VERSION ""

NS_ :

BS_:

BU_: PDU ELVIS ASSI ECU_LV Dashboard

BO_ 1285 ECU_error: 1 ECU_LV
 SG_ Error_code : 7|8@0+ (1,0) [0|255] "" Vector__XXX

BO_ 1 ECU_State: 1 ECU_LV
 SG_ Orion_state : 3|3@0+ (1,0) [0|7] "" Vector__XXX
 SG_ Heartbeat : 0|1@0+ (1,0) [0|1] "" Vector__XXX

BO_ 277 Brake_pressures: 4 ECU_LV
 SG_ Brake_rear : 23|16@0+ (0.004,0) [0|262.14] "" Vector__XXX
 SG_ Brake_front : 7|16@0+ (0.004,0) [0|262.14] "" Vector__XXX

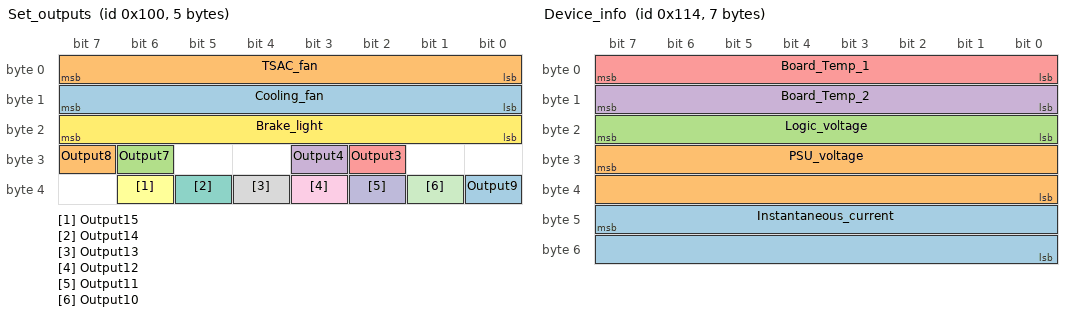
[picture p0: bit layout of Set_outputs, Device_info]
BO_ 256 Set_outputs: 5 PDU
 SG_ Output9 : 32|1@0+ (1,0) [0|1] "" Vector__XXX
 SG_ Output8 : 31|1@0+ (1,0) [0|1] "" Vector__XXX
 SG_ Output7 : 30|1@0+ (1,0) [0|1] "" Vector__XXX
 SG_ Output4 : 27|1@0+ (1,0) [0|1] "" Vector__XXX
 SG_ Output3 : 26|1@0+ (1,0) [0|1] "" Vector__XXX
 SG_ Output15 : 38|1@0+ (1,0) [0|1] "" Vector__XXX
 SG_ Output14 : 37|1@0+ (1,0) [0|1] "" Vector__XXX
 SG_ Output13 : 36|1@0+ (1,0) [0|1] "" Vector__XXX
 SG_ Output12 : 35|1@0+ (1,0) [0|1] "" Vector__XXX
 SG_ Output11 : 34|1@0+ (1,0) [0|1] "" Vector__XXX
 SG_ Output10 : 33|1@0+ (1,0) [0|1] "" Vector__XXX
 SG_ Brake_light : 23|8@0+ (1,0) [0|255] "" Vector__XXX
 SG_ Cooling_fan : 15|8@0+ (1,0) [0|255] "" Vector__XXX
 SG_ TSAC_fan : 7|8@0+ (1,0) [0|255] "" Vector__XXX

BO_ 273 Output_states: 3 PDU
 SG_ Fanspeed : 23|8@0+ (1,0) [0|255] "" Vector__XXX
 SG_ State : 7|16@0+ (1,0) [0|65535] "" Vector__XXX

BO_ 272 Inputs: 2 PDU
 SG_ Watercool_temp2 : 15|8@0+ (1,0) [0|255] "" Vector__XXX
 SG_ Watercool_temp1 : 7|8@0+ (1,0) [0|255] "" Vector__XXX

BO_ 276 Device_info: 7 PDU
 SG_ Instantaneous_current : 47|16@0+ (1,0) [0|65535] "" Vector__XXX
 SG_ PSU_voltage : 31|16@0+ (1,0) [0|65535] "" Vector__XXX
 SG_ Logic_voltage : 23|8@0+ (1,0) [0|255] "" Vector__XXX
 SG_ Board_Temp_2 : 15|8@0+ (1,0) [0|255] "" Vector__XXX
 SG_ Board_Temp_1 : 7|8@0+ (1,0) [0|255] "" Vector__XXX

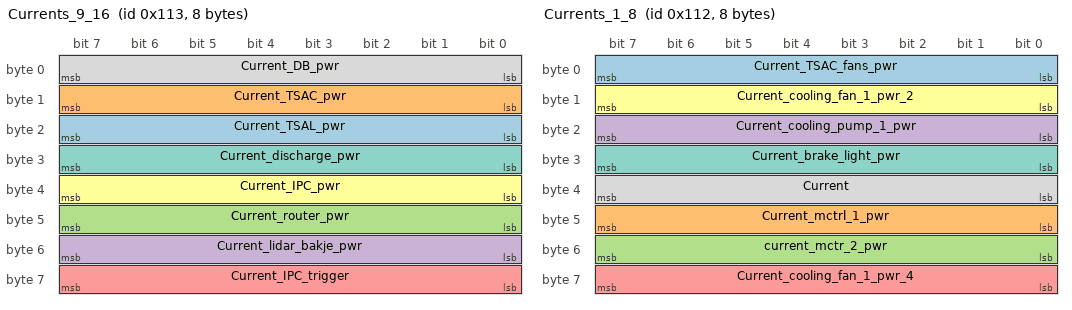
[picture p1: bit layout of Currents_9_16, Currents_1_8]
BO_ 275 Currents_9_16: 8 PDU
 SG_ Current_TSAL_pwr : 23|8@0+ (1,0) [0|255] "" Vector__XXX
 SG_ Current_TSAC_pwr : 15|8@0+ (1,0) [0|255] "" Vector__XXX
 SG_ Current_router_pwr : 47|8@0+ (1,0) [0|255] "" Vector__XXX
 SG_ Current_lidar_bakje_pwr : 55|8@0+ (1,0) [0|255] "" Vector__XXX
 SG_ Current_IPC_trigger : 63|8@0+ (1,0) [0|255] "" Vector__XXX
 SG_ Current_IPC_pwr : 39|8@0+ (1,0) [0|255] "" Vector__XXX
 SG_ Current_discharge_pwr : 31|8@0+ (1,0) [0|255] "" Vector__XXX
 SG_ Current_DB_pwr : 7|8@0+ (1,0) [0|255] "" Vector__XXX

BO_ 274 Currents_1_8: 8 PDU
 SG_ Current_TSAC_fans_pwr : 7|8@0+ (1,0) [0|255] "" Vector__XXX
 SG_ Current_mctrl_1_pwr : 47|8@0+ (1,0) [0|255] "" Vector__XXX
 SG_ current_mctr_2_pwr : 55|8@0+ (1,0) [0|255] "" Vector__XXX
 SG_ Current_cooling_pump_1_pwr : 23|8@0+ (1,0) [0|255] "" Vector__XXX
 SG_ Current_cooling_fan_1_pwr_4 : 63|8@0+ (1,0) [0|255] "" Vector__XXX
 SG_ Current_cooling_fan_1_pwr_2 : 15|8@0+ (1,0) [0|255] "" Vector__XXX
 SG_ Current_brake_light_pwr : 31|8@0+ (1,0) [0|255] "" Vector__XXX
 SG_ Current : 39|8@0+ (1,0) [0|255] "" Vector__XXX

BO_ 16 PDU_Heartbeat: 1 PDU
 SG_ Heartbeat : 0|1@0+ (1,0) [0|1] "" Vector__XXX

BO_ 768 DB_Commands: 1 Dashboard
 SG_ TS_start : 6|1@0+ (1,0) [0|1] "" Vector__XXX
 SG_ RTD_start : 7|1@0+ (1,0) [0|1] "" Vector__XXX

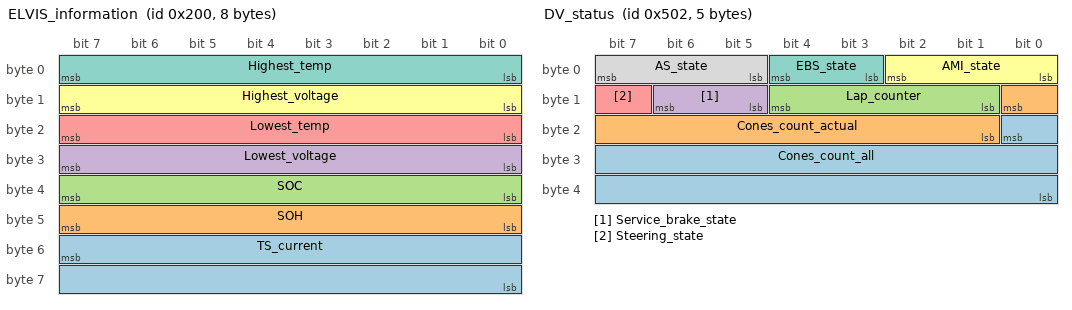
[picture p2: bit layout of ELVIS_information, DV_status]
BO_ 512 ELVIS_information: 8 ELVIS
 SG_ TS_current : 55|16@0+ (1,0) [0|65535] "" Vector__XXX
 SG_ SOH : 47|8@0+ (1,0) [0|255] "" Vector__XXX
 SG_ SOC : 39|8@0+ (1,0) [0|255] "" Vector__XXX
 SG_ Lowest_voltage : 31|8@0+ (1,0) [0|255] "" Vector__XXX
 SG_ Lowest_temp : 23|8@0+ (1,0) [0|255] "" Vector__XXX
 SG_ Highest_voltage : 15|8@0+ (1,0) [0|255] "" Vector__XXX
 SG_ Highest_temp : 7|8@0+ (1,0) [0|255] "" Vector__XXX

BO_ 1282 DV_status: 5 ECU_LV
 SG_ Cones_count_all : 16|17@0+ (1,0) [0|131071] "" Vector__XXX
 SG_ Cones_count_actual : 8|8@0+ (1,0) [0|255] "" Vector__XXX
 SG_ Lap_counter : 12|4@0+ (1,0) [0|15] "" Vector__XXX
 SG_ Service_brake_state : 14|2@0+ (1,0) [0|2] "" Vector__XXX
 SG_ Steering_state : 15|1@0+ (1,0) [0|1] "" Vector__XXX
 SG_ AMI_state : 2|3@0+ (1,0) [0|5] "" Vector__XXX
 SG_ EBS_state : 4|2@0+ (1,0) [0|2] "" Vector__XXX
 SG_ AS_state : 7|3@0+ (1,0) [0|4] "" Vector__XXX

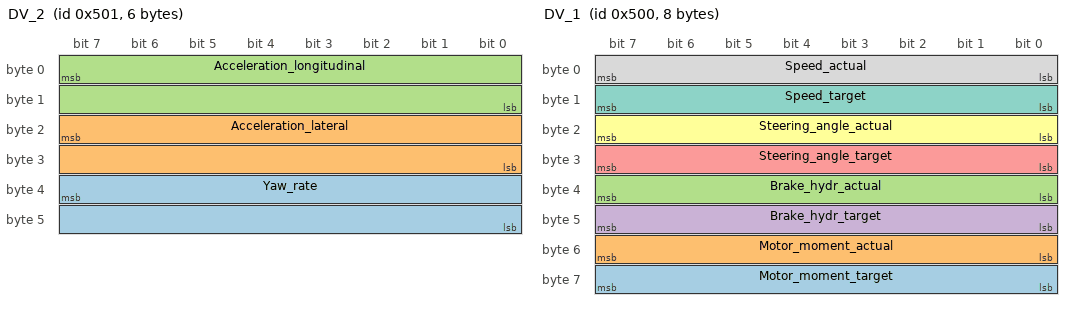
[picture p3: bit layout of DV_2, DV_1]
BO_ 1281 DV_2: 6 ECU_LV
 SG_ Yaw_rate : 39|16@0- (0.0078125,0) [-256|255.9921875] "deg/s" Vector__XXX
 SG_ Acceleration_lateral : 23|16@0- (0.001953125,0) [-64|63.998046875] "m/s^2" Vector__XXX
 SG_ Acceleration_longitudinal : 7|16@0- (0.001953125,0) [-64|63.998046875] "m/s^2" Vector__XXX

BO_ 1280 DV_1: 8 ECU_LV
 SG_ Motor_moment_target : 63|8@0- (1,0) [-100|100] "%" Vector__XXX
 SG_ Motor_moment_actual : 55|8@0- (1,0) [-100|100] "%" Vector__XXX
 SG_ Brake_hydr_actual : 39|8@0+ (1,0) [0|100] "%" Vector__XXX
 SG_ Brake_hydr_target : 47|8@0+ (1,0) [0|100] "%" Vector__XXX
 SG_ Steering_angle_target : 31|8@0- (0.5,0) [-64|63.5] "deg" Vector__XXX
 SG_ Steering_angle_actual : 23|8@0- (0.5,0) [-64|63.5] "deg" Vector__XXX
 SG_ Speed_target : 15|8@0+ (1,0) [0|255] "km/h" Vector__XXX
 SG_ Speed_actual : 7|8@0+ (1,0) [0|255] "km/h" Vector__XXX

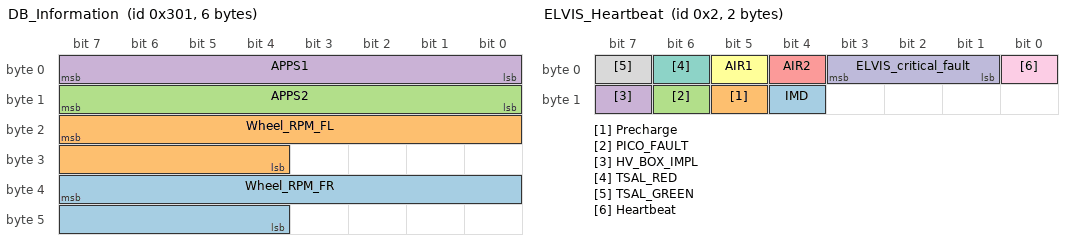
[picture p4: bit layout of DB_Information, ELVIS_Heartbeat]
BO_ 769 DB_Information: 6 Dashboard
 SG_ Wheel_RPM_FR : 39|12@0+ (1,0) [0|3000] "RPM" Vector__XXX
 SG_ Wheel_RPM_FL : 23|12@0+ (1,0) [0|3000] "RPM" Vector__XXX
 SG_ APPS2 : 15|8@0+ (1,0) [0|100] "%" Vector__XXX
 SG_ APPS1 : 7|8@0+ (1,0) [0|100] "%" Vector__XXX

BO_ 2 ELVIS_Heartbeat: 2 ELVIS
 SG_ IMD : 12|1@0+ (1,0) [0|1] "" Vector__XXX
 SG_ Precharge : 13|1@0+ (1,0) [0|1] "" Vector__XXX
 SG_ PICO_FAULT : 14|1@0+ (1,0) [0|1] "" Vector__XXX
 SG_ HV_BOX_IMPL : 15|1@0+ (1,0) [0|1] "" Vector__XXX
 SG_ AIR2 : 4|1@0+ (1,0) [0|1] "" Vector__XXX
 SG_ AIR1 : 5|1@0+ (1,0) [0|1] "" Vector__XXX
 SG_ TSAL_RED : 6|1@0+ (1,0) [0|1] "" Vector__XXX
 SG_ TSAL_GREEN : 7|1@0+ (1,0) [0|1] "" Vector__XXX
 SG_ Heartbeat : 0|1@0+ (1,0) [0|1] "" Vector__XXX
 SG_ ELVIS_critical_fault : 3|3@0+ (1,0) [0|5] "" Vector__XXX

BO_ 3 DB_Heartbeat: 1 Dashboard
 SG_ Heartbeat : 0|1@0+ (1,0) [0|1] "" Vector__XXX

BO_ 4 ASSI_Heartbeat: 1 ASSI
 SG_ Heartbeat : 0|1@0+ (1,0) [0|1] "" Vector__XXX

CM_ SG_ 256 Output9 "Turn specific output on or off";
CM_ SG_ 256 Output8 "Turn specific output on or off";
CM_ SG_ 256 Output7 "Turn specific output on or off";
CM_ SG_ 256 Output4 "Turn specific output on or off";
CM_ SG_ 256 Output3 "Turn specific output on or off";
CM_ SG_ 256 Output15 "Turn specific output on or off";
CM_ SG_ 256 Output14 "Turn specific output on or off";
CM_ SG_ 256 Output13 "Turn specific output on or off";
CM_ SG_ 256 Output12 "Turn specific output on or off";
CM_ SG_ 256 Output11 "Turn specific output on or off";
CM_ SG_ 256 Output10 "Turn specific output on or off";
CM_ SG_ 273 State "State of PDU outputs";
VAL_ 1 Orion_state 6 "ERROR" 5 "R2D" 4 "R2D_READY" 3 "TS_ACTIVE" 2 "TS_ACTIVATING" 1 "TS_READY" 0 "INIT" ;
VAL_ 1282 Service_brake_state 3 "available" 2 "engaged" 1 "disengaged" 0 "UNKNOWN" ;
VAL_ 1282 AMI_state 5 "inspection" 6 "autocross" 4 "braketest" 3 "trackdrive" 2 "skidpad" 1 "acceleration" 0 "UNKNOWN" ;
VAL_ 1282 EBS_state 2 "armed" 3 "activated" 1 "unavailable" 0 "UNKNOWN" ;
VAL_ 1282 AS_state 5 "finish" 4 "emergency_brake" 3 "driving" 2 "ready" 1 "off" 0 "unknown" ;
VAL_ 2 ELVIS_critical_fault 5 "OVERTEMPERATURE" 4 "UNDERTEMPERATURE" 3 "OVERVOLTAGE" 2 "UNDERVOLTAGE" 1 "UNKNOWN_FAULT" 0 "OKAY" ;
